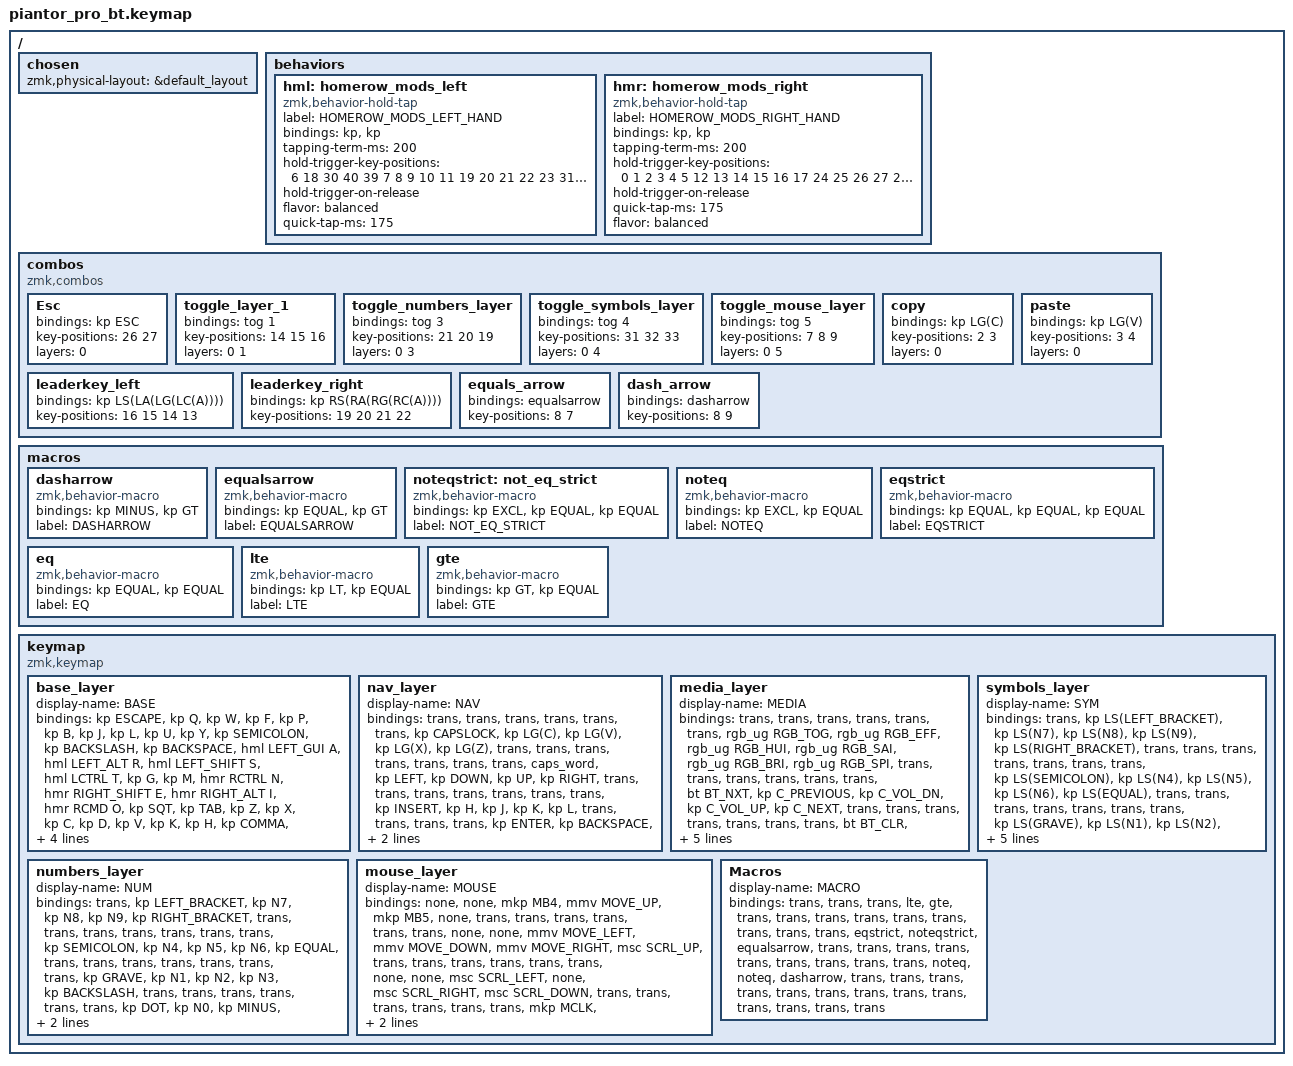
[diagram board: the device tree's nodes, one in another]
/*
 * Copyright (c) 2020 The ZMK Contributors
 *
 * SPDX-License-Identifier: MIT
 */

#include <behaviors.dtsi>
#include <dt-bindings/zmk/bt.h>
#include <dt-bindings/zmk/keys.h>
#include <dt-bindings/zmk/pointing.h>
#include <dt-bindings/zmk/rgb.h>

/ {
    chosen { zmk,physical-layout = &default_layout; };
};

/ {
    behaviors {
        hml: homerow_mods_left {
            compatible = "zmk,behavior-hold-tap";
            label = "HOMEROW_MODS_LEFT_HAND";
            bindings = <&kp>, <&kp>;

            #binding-cells = <2>;
            tapping-term-ms = <200>;
            hold-trigger-key-positions = <6 18 30 40 39 7 8 9 10 11 19 20 21 22 23 31 32 33 34 35 41>;
            hold-trigger-on-release;
            flavor = "balanced";
            quick-tap-ms = <175>;
        };

        hmr: homerow_mods_right {
            compatible = "zmk,behavior-hold-tap";
            label = "HOMEROW_MODS_RIGHT_HAND";
            bindings = <&kp>, <&kp>;

            #binding-cells = <2>;
            tapping-term-ms = <200>;
            hold-trigger-key-positions = <0 1 2 3 4 5 12 13 14 15 16 17 24 25 26 27 28 29 36 37 38>;
            hold-trigger-on-release;
            quick-tap-ms = <175>;
            flavor = "balanced";
        };
    };

    combos {
        compatible = "zmk,combos";

        Esc {
            bindings = <&kp ESC>;
            key-positions = <26 27>;
            layers = <0>;
        };

        toggle_layer_1 {
            bindings = <&tog 1>;
            key-positions = <14 15 16>;
            layers = <0 1>;
        };

        toggle_numbers_layer {
            bindings = <&tog 3>;
            key-positions = <21 20 19>;
            layers = <0 3>;
        };

        toggle_symbols_layer {
            bindings = <&tog 4>;
            key-positions = <31 32 33>;
            layers = <0 4>;
        };

        toggle_mouse_layer {
            bindings = <&tog 5>;
            key-positions = <7 8 9>;
            layers = <0 5>;
        };

        copy {
            bindings = <&kp LG(C)>;
            key-positions = <2 3>;
            layers = <0>;
        };

        paste {
            bindings = <&kp LG(V)>;
            key-positions = <3 4>;
            layers = <0>;
        };

        leaderkey_left {
            bindings = <&kp LS(LA(LG(LC(A))))>;
            key-positions = <16 15 14 13>;
        };

        leaderkey_right {
            bindings = <&kp RS(RA(RG(RC(A))))>;
            key-positions = <19 20 21 22>;
        };

        equals_arrow {
            bindings = <&equalsarrow>;
            key-positions = <8 7>;
        };

        dash_arrow {
            bindings = <&dasharrow>;
            key-positions = <8 9>;
        };
    };

    macros {
        dasharrow: dasharrow {
            compatible = "zmk,behavior-macro";
            #binding-cells = <0>;
            bindings = <&kp MINUS &kp GT>;
            label = "DASHARROW";
        };

        equalsarrow: equalsarrow {
            compatible = "zmk,behavior-macro";
            #binding-cells = <0>;
            bindings = <&kp EQUAL &kp GT>;
            label = "EQUALSARROW";
        };

        noteqstrict: not_eq_strict {
            compatible = "zmk,behavior-macro";
            #binding-cells = <0>;
            bindings = <&kp EXCL &kp EQUAL &kp EQUAL>;
            label = "NOT_EQ_STRICT";
        };

        noteq: noteq {
            compatible = "zmk,behavior-macro";
            #binding-cells = <0>;
            bindings = <&kp EXCL &kp EQUAL>;
            label = "NOTEQ";
        };

        eqstrict: eqstrict {
            compatible = "zmk,behavior-macro";
            #binding-cells = <0>;
            bindings = <&kp EQUAL &kp EQUAL &kp EQUAL>;
            label = "EQSTRICT";
        };

        eq: eq {
            compatible = "zmk,behavior-macro";
            #binding-cells = <0>;
            bindings = <&kp EQUAL &kp EQUAL>;
            label = "EQ";
        };

        lte: lte {
            compatible = "zmk,behavior-macro";
            #binding-cells = <0>;
            bindings = <&kp LT &kp EQUAL>;
            label = "LTE";
        };

        gte: gte {
            compatible = "zmk,behavior-macro";
            #binding-cells = <0>;
            bindings = <&kp GT &kp EQUAL>;
            label = "GTE";
        };
    };

    keymap {
        compatible = "zmk,keymap";

        base_layer {
            display-name = "BASE";

            // --------------------------------------------------------------------------------
            // |  TAB |  Q  |  W  |  E  |  R  |  T  |  Y  |  U   |  I  |  O  |  P  | BSPC |
            // | CTRL |  A  |  S  |  D  |  F  |  G  |  H  |  J   |  K  |  L  |  ;  |  '   |
            // | SHFT |  Z  |  X  |  C  |  V  |  B  |  N  |  M   |  ,  |  .  |  /  | ESC  |
            //                    | GUI | LWR | SPC | ENT | RSE  | ALT |

            bindings = <
&kp ESCAPE  &kp Q  &kp W  &kp F  &kp P  &kp B  &kp J  &kp L  &kp U  &kp Y  &kp SEMICOLON  &kp BACKSLASH  &kp BACKSPACE  &hml LEFT_GUI A  &hml LEFT_ALT R  &hml LEFT_SHIFT S  &hml LCTRL T  &kp G  &kp M  &hmr RCTRL N  &hmr RIGHT_SHIFT E  &hmr RIGHT_ALT I  &hmr RCMD O  &kp SQT  &kp TAB  &kp Z  &kp X  &kp C  &kp D  &kp V  &kp K  &kp H  &kp COMMA  &kp DOT  &lt 6 FSLH  &kp MINUS  &lt 2 ESCAPE  &lt 1 SPACE  &hml LS(LA(LG(LCTRL))) TAB  &lt 4 ENTER  &lt 3 RCTRL  &lt 5 DELETE
            >;

            label = "BASE";
        };

        nav_layer {
            display-name = "NAV";

            // -----------------------------------------------------------------------------------------
            // |  TAB |  1  |  2  |  3  |  4  |  5    |  6  |  7  |  8  |  9  |  0  | BSPC |
            // | CTRL | BT1 | BT2 | BT3 | BT4 | BT5   | LFT | DWN |  UP | RGT |     |      |
            // | SHFT | BTCR| RGB | RST | BOOT| Unlock|     |     |     |     |     |      |
            //                    | GUI |     | SPC   | ENT |     | ALT |

            bindings = <
&trans  &trans  &trans  &trans  &trans  &trans  &kp CAPSLOCK  &kp LG(C)  &kp LG(V)  &kp LG(X)  &kp LG(Z)  &trans  &trans  &trans  &trans  &trans  &trans  &trans  &caps_word  &kp LEFT  &kp DOWN  &kp UP  &kp RIGHT  &trans  &trans  &trans  &trans  &trans  &trans  &trans  &kp INSERT  &kp H  &kp J  &kp K  &kp L  &trans  &trans  &trans  &trans  &kp ENTER  &kp BACKSPACE  &kp DEL
            >;

            label = "NAV";
        };

        media_layer {
            display-name = "MEDIA";
            bindings = <
&trans  &trans  &trans  &trans  &trans  &trans  &rgb_ug RGB_TOG  &rgb_ug RGB_EFF  &rgb_ug RGB_HUI  &rgb_ug RGB_SAI  &rgb_ug RGB_BRI  &rgb_ug RGB_SPI  &trans  &trans  &trans  &trans  &trans  &trans  &bt BT_NXT  &kp C_PREVIOUS  &kp C_VOL_DN  &kp C_VOL_UP  &kp C_NEXT  &trans  &trans  &trans  &trans  &trans  &trans  &trans  &bt BT_CLR  &rgb_ug RGB_EFR  &rgb_ug RGB_HUD  &rgb_ug RGB_SAD  &rgb_ug RGB_BRD  &rgb_ug RGB_SPD  &trans  &trans  &trans  &kp C_STOP  &kp C_PLAY_PAUSE  &kp C_MUTE
            >;

            label = "MEDIA";
        };

        numbers_layer {
            display-name = "NUM";
            bindings = <
&trans  &kp LEFT_BRACKET  &kp N7  &kp N8  &kp N9  &kp RIGHT_BRACKET  &trans  &trans  &trans  &trans  &trans  &trans  &trans  &kp SEMICOLON  &kp N4  &kp N5  &kp N6  &kp EQUAL  &trans  &trans  &trans  &trans  &trans  &trans  &trans  &kp GRAVE  &kp N1  &kp N2  &kp N3  &kp BACKSLASH  &trans  &trans  &trans  &trans  &trans  &trans  &kp DOT  &kp N0  &kp MINUS  &trans  &trans  &trans
            >;

            label = "NUM";
        };

        symbols_layer {
            display-name = "SYM";
            bindings = <
&trans  &kp LS(LEFT_BRACKET)  &kp LS(N7)  &kp LS(N8)  &kp LS(N9)  &kp LS(RIGHT_BRACKET)  &trans  &trans  &trans  &trans  &trans  &trans  &trans  &kp LS(SEMICOLON)  &kp LS(N4)  &kp LS(N5)  &kp LS(N6)  &kp LS(EQUAL)  &trans  &trans  &trans  &trans  &trans  &trans  &trans  &kp LS(GRAVE)  &kp LS(N1)  &kp LS(N2)  &kp LS(N3)  &kp LS(BACKSLASH)  &trans  &trans  &trans  &trans  &trans  &trans  &kp LEFT_PARENTHESIS  &kp RIGHT_PARENTHESIS  &kp LS(MINUS)  &trans  &trans  &trans
            >;

            label = "SYM";
        };

        mouse_layer {
            display-name = "MOUSE";
            bindings = <
&none  &none  &mkp MB4  &mmv MOVE_UP  &mkp MB5  &none  &trans  &trans  &trans  &trans  &trans  &trans  &none  &none  &mmv MOVE_LEFT  &mmv MOVE_DOWN  &mmv MOVE_RIGHT  &msc SCRL_UP  &trans  &trans  &trans  &trans  &trans  &trans  &none  &none  &msc SCRL_LEFT  &none  &msc SCRL_RIGHT  &msc SCRL_DOWN  &trans  &trans  &trans  &trans  &trans  &trans  &mkp MCLK  &mkp LCLK  &mkp RCLK  &trans  &trans  &trans
            >;

            label = "MOUSE";
        };

        Macros {
            display-name = "MACRO";
            bindings = <
&trans  &trans  &trans  &lte  &gte  &trans  &trans  &trans  &trans  &trans  &trans  &trans  &trans  &trans  &eqstrict  &noteqstrict  &equalsarrow  &trans  &trans  &trans  &trans  &trans  &trans  &trans  &trans  &trans  &noteq  &noteq  &dasharrow  &trans  &trans  &trans  &trans  &trans  &trans  &trans  &trans  &trans  &trans  &trans  &trans  &trans
            >;
        };
    };
};
